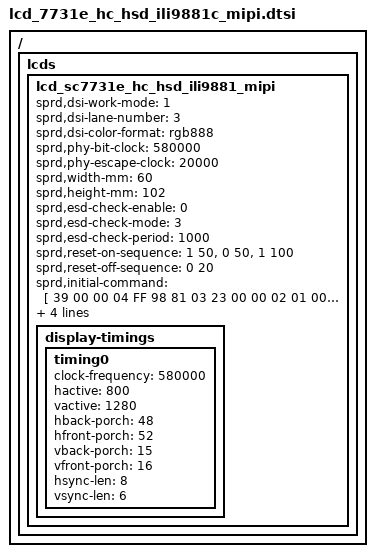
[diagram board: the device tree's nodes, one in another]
/ { lcds {
	lcd_sc7731e_hc_hsd_ili9881_mipi: lcd_sc7731e_hc_hsd_ili9881_mipi {

		sprd,dsi-work-mode = <1>;
		sprd,dsi-lane-number = <3>;
		sprd,dsi-color-format = "rgb888";

		sprd,phy-bit-clock = <580000>;
		sprd,phy-escape-clock = <20000>;

		sprd,width-mm = <60>;
		sprd,height-mm = <102>;

		sprd,esd-check-enable = <0>;
		sprd,esd-check-mode = <3>;
		sprd,esd-check-period = <1000>;
		/*sprd,esd-check-register = <0x0A>;*/
		/*sprd,esd-check-value = <0x9C>;*/

		sprd,reset-on-sequence = <1 50>, <0 50>, <1 100>;
		sprd,reset-off-sequence = <0 20>;
		sprd,initial-command = [
		
39 00 00 04 FF 98 81 03
23 00 00 02 01 00
23 00 00 02 02 00
23 00 00 02 03 73     //STA Width 4H
23 00 00 02 04 00
23 00 00 02 05 00
23 00 00 02 06 0A     //STVA Rise start
23 00 00 02 07 00
23 00 00 02 08 00
23 00 00 02 09 20     //Detail A&B 3.5-4.0us
23 00 00 02 0A 20     //Detail A&B 3.5-4.0us
23 00 00 02 0B 00
23 00 00 02 0C 00
23 00 00 02 0D 00
23 00 00 02 0E 00
23 00 00 02 0F 20     //Detail A&B 3.5-4.0us
23 00 00 02 10 20     //Detail A&B 3.5-4.0us 
23 00 00 02 11 00
23 00 00 02 12 00
23 00 00 02 13 00
23 00 00 02 14 00
23 00 00 02 15 00
23 00 00 02 16 00 
23 00 00 02 17 00
23 00 00 02 18 00
23 00 00 02 19 00
23 00 00 02 1A 00
23 00 00 02 1B 00
23 00 00 02 1C 00
23 00 00 02 1D 00
23 00 00 02 1E 40
23 00 00 02 1F 80
23 00 00 02 20 06    //CLKA Rise START
23 00 00 02 21 01    //CLKA FALL END
23 00 00 02 22 00
23 00 00 02 23 00
23 00 00 02 24 00
23 00 00 02 25 00
23 00 00 02 26 00
23 00 00 02 27 00
23 00 00 02 28 33    //CLK_x_Numb[2:0]  Phase_CLK[2:0]
23 00 00 02 29 03    //Overlap_CLK[3:0]
23 00 00 02 2A 00
23 00 00 02 2B 00
23 00 00 02 2C 00
23 00 00 02 2D 00
23 00 00 02 2E 00
23 00 00 02 2F 00
23 00 00 02 30 00
23 00 00 02 31 00
23 00 00 02 32 00
23 00 00 02 33 00
23 00 00 02 34 04     //04 GPWR1/2 non overlap time 2.62us
23 00 00 02 35 00
23 00 00 02 36 00
23 00 00 02 37 00
23 00 00 02 38 3C     //78 FOR GPWR1/2 cycle 2 s
23 00 00 02 39 00
23 00 00 02 3A 00 
23 00 00 02 3B 00
23 00 00 02 3C 00
23 00 00 02 3D 00
23 00 00 02 3E 00
23 00 00 02 3F 00
23 00 00 02 40 00
23 00 00 02 41 00
23 00 00 02 42 00
23 00 00 02 43 00
23 00 00 02 44 00
23 00 00 02 50 10
23 00 00 02 51 32
23 00 00 02 52 54
23 00 00 02 53 76
23 00 00 02 54 98
23 00 00 02 55 ba
23 00 00 02 56 10
23 00 00 02 57 32
23 00 00 02 58 54
23 00 00 02 59 76
23 00 00 02 5A 98
23 00 00 02 5B ba
23 00 00 02 5C dc
23 00 00 02 5D fe
23 00 00 02 5E 00
23 00 00 02 5F 01      //GOUT1_FW
23 00 00 02 60 00      //GOUT2_BW
23 00 00 02 61 15      //GOUT3_GPWR1
23 00 00 02 62 14      //GOUT4_GPWR2
23 00 00 02 63 0E      //GOUT5_CLK1_R
23 00 00 02 64 0F      //GOUT6_CLK2_R
23 00 00 02 65 0C      //GOUT7_CLK3_R
23 00 00 02 66 0D      //GOUT8_CLK4_R
23 00 00 02 67 06      //GOUT9_STV1_R
23 00 00 02 68 02
23 00 00 02 69 02
23 00 00 02 6A 02
23 00 00 02 6B 02
23 00 00 02 6C 02
23 00 00 02 6D 02
23 00 00 02 6E 07       //GOUT16_STV2_R
23 00 00 02 6F 02       //GOUT17_VGL
23 00 00 02 70 02       //GOUT18_VGL
23 00 00 02 71 02       //GOUT19_VGL
23 00 00 02 72 02       
23 00 00 02 73 02       
23 00 00 02 74 02       
23 00 00 02 75 01       //FW
23 00 00 02 76 00       //BW
23 00 00 02 77 14       //GPWR1
23 00 00 02 78 15       //GPWR2
23 00 00 02 79 0E       //CLK1_R
23 00 00 02 7A 0F       //CLK2_R
23 00 00 02 7B 0C       //CLK3_R
23 00 00 02 7C 0D       //CLK4_R
23 00 00 02 7D 06       //STV1_R
23 00 00 02 7E 02       
23 00 00 02 7F 02       
23 00 00 02 80 02       
23 00 00 02 81 02       
23 00 00 02 82 02       
23 00 00 02 83 02       
23 00 00 02 84 07       //STV2_R
23 00 00 02 85 02       //VGL
23 00 00 02 86 02       //VGL
23 00 00 02 87 02       //VGL 
23 00 00 02 88 02        
23 00 00 02 89 02        
23 00 00 02 8A 02        
39 00 00 04 FF 98 81 04
23 00 00 02 00 00       //Set VCORE voltage =1.5V
23 00 00 02 6C 15        //Set VCORE voltage =1.5V
23 00 00 02 6E 2A        //di_pwr_reg=0 for power mode 2A //VGH clamp 15V
23 00 00 02 6F 33        // reg vcl + pumping ratio VGH=3x VGL=-2.5x
23 00 00 02 3A 92        //POWER SAVING
23 00 00 02 8D 1A        //VGL clamp -11V
23 00 00 02 87 BA        //ESD               
23 00 00 02 26 76                
23 00 00 02 B2 D1        
23 00 00 02 B5 27        //GMA BIAS
23 00 00 02 31 75        //SRC BIAS
23 00 00 02 30 03        //SRC OUTPUT BIAS
23 00 00 02 3B 98        //PUMP SHIFT CLK
23 00 00 02 35 17        //HZ_opt
23 00 00 02 33 14        //Blanking frame ÔO¶¨žéGND 
23 00 00 02 38 01
23 00 00 02 39 00
39 00 00 04 FF 98 81 01
23 00 00 02 22 0A		//BGR, SS
23 00 00 02 31 00		//column inversion
23 00 00 02 53 3C		//VCOM1
23 00 00 02 55 8F		//VCOM2
23 00 00 02 50 C0		//VREG1OUT=5V
23 00 00 02 51 C0		//VREG2OUT=-5V
23 00 00 02 60 14               //SDT
23 00 00 02 A0 08		//VP255	Gamma P
23 00 00 02 A1 10               //VP251        
23 00 00 02 A2 25               //VP247        
23 00 00 02 A3 00               //VP243        
23 00 00 02 A4 24               //VP239        
23 00 00 02 A5 19               //VP231        
23 00 00 02 A6 12               //VP219        
23 00 00 02 A7 1B               //VP203        
23 00 00 02 A8 77               //VP175        
23 00 00 02 A9 19               //VP144        
23 00 00 02 AA 25               //VP111        
23 00 00 02 AB 6E               //VP80         
23 00 00 02 AC 20               //VP52         
23 00 00 02 AD 17               //VP36         
23 00 00 02 AE 54               //VP24         
23 00 00 02 AF 24               //VP16         
23 00 00 02 B0 27               //VP12         
23 00 00 02 B1 52               //VP8          
23 00 00 02 B2 63               //VP4          
23 00 00 02 B3 39               //VP0                                                         
23 00 00 02 C0 08		//VN255 GAMMA N
23 00 00 02 C1 20               //VN251        
23 00 00 02 C2 23               //VN247        
23 00 00 02 C3 22               //VN243        
23 00 00 02 C4 06               //VN239        
23 00 00 02 C5 34               //VN231        
23 00 00 02 C6 25               //VN219        
23 00 00 02 C7 20               //VN203        
23 00 00 02 C8 86               //VN175        
23 00 00 02 C9 1F               //VN144        
23 00 00 02 CA 2B               //VN111        
23 00 00 02 CB 74               //VN80         
23 00 00 02 CC 16               //VN52         
23 00 00 02 CD 1B               //VN36         
23 00 00 02 CE 46               //VN24         
23 00 00 02 CF 21               //VN16         
23 00 00 02 D0 29               //VN12         
23 00 00 02 D1 54               //VN8          
23 00 00 02 D2 65               //VN4          
23 00 00 02 D3 39               //VN0
39 00 00 04 FF 98 81 00
13 78 00 01 11    
13 64 00 01 29 
			];
		sprd,sleep-in-command = [
			13 0A 00 01 28
			13 78 00 01 10
			];
		sprd,sleep-out-command = [
			13 78 00 01 11
			13 64 00 01 29
			];

		display-timings {
			timing0 {
			clock-frequency = <580000>;
			hactive = <800>;
			vactive = <1280>;
			hback-porch = <48>;
			hfront-porch = <52>;
			vback-porch = <15>;
			vfront-porch = <16>;
			hsync-len = <8>;
			vsync-len = <6>;
			};
		};
	};
};};

